# SIM3U166_B register map
File version: 1
CPU: 
Registers are 32-bit, read-write, reset 0x0 unless marked. A register's access mark holds for its fields unless they carry their own. Offsets are from the block's base; [hi:lo] are bit positions; {n}, {i} and the like mark numbered series.

## EPCA_0
Base 0x4000E000
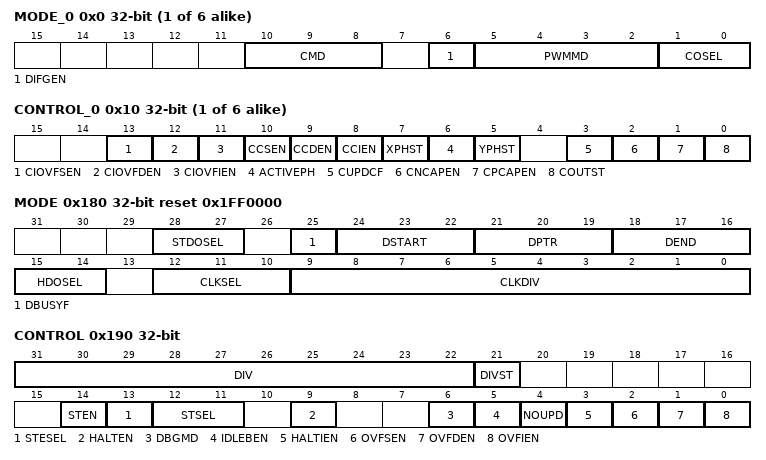
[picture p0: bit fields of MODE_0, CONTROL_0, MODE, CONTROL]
{0x0+0x40*i} MODE_{i} (i=0..5) — Channel Capture/Compare Mode
  [10:8] CMD — Channel Operating Mode.
    0=EDGE_PWM (Configure the channel for edge-aligned PWM mode.); 1=CENTER_ALIGNED_PWM (Configure the channel for center-aligned PWM mode.); 2=HF_SQUARE_WAVE (Configure the channel for high-frequency/square-wave mode.); 3=TIMER_CAPTURE (Configure the channel for timer/capture mode.); 4=N_BIT_PWM (Configure the channel for n-bit edge-aligned PWM mode.)
  [6] DIFGEN — Differential Signal Generator Enable.
    0=DISABLED (Disable the differential signal generator. The channel will output a single non-differential output.); 1=ENABLED (Enable the differential signal generator. The channel will output two differential outputs: X Phase (XPH) and Y Phase (YPH).)
  [5:2] PWMMD — PWM N-Bit Mode.
  [1:0] COSEL — Channel Output Function Select.
    0=TOGGLE_OUTPUT (Toggle the channel output at the next capture/compare, overflow, or intermediate event.); 1=SET_OUTPUT (Set the channel output at the next capture/compare, overflow, or intermediate event.); 2=CLEAR_OUTPUT (Clear the output at the next capture/compare, overflow, or intermediate event.); 3=NO_CHANGE (Capture/Compare, overflow, or intermediate events do not control the output state.)
{0x10+0x40*i} CONTROL_{i} (i=0..5) — Channel Capture/Compare Control
  [13] CIOVFSEN — Intermediate Overflow Synchronization Signal Enable.
    0=DISABLED (Do not send a synchronization signal when a channel intermediate overflow event occurs.); 1=ENABLED (Send a synchronization signal when a channel intermediate overflow occurs.)
  [12] CIOVFDEN — Intermediate Overflow DMA Request Enable.
    0=DISABLED (Do not request DMA data when a channel intermediate overflow event occurs.); 1=ENABLED (Request DMA data when a channel intermediate overflow event occurs.)
  [11] CIOVFIEN — Intermediate Overflow Interrupt Enable.
    0=DISABLED (Disable the channel intermediate overflow interrupt.); 1=ENABLED (Enable the channel intermediate overflow interrupt.)
  [10] CCSEN — Capture/Compare Synchronization Signal Enable.
    0=DISABLED (Do not send a synchronization signal when a channel capture/compare event occurs.); 1=ENABLED (Send a synchronization signal when a channel capture/compare event occurs.)
  [9] CCDEN — Capture/Compare DMA Request Enable.
    0=DISABLED (Do not request DMA data when a channel capture/compare event occurs.); 1=ENABLED (Request DMA data when a channel capture/compare event occurs.)
  [8] CCIEN — Capture/Compare Interrupt Enable.
    0=DISABLED (Disable the channel capture/compare interrupt.); 1=ENABLED (Enable the channel capture/compare interrupt.)
  [7] XPHST — Differential X Phase State.
    0=LOW (Set the X Phase output state to low.); 1=HIGH (Set the X Phase output state to high.)
  [6] ACTIVEPH — Active Channel Select.
    0=YACTIVE (The Y Phase is active and X Phase is inactive.); 1=XACTIVE (The X Phase is active and Y Phase is inactive.)
  [5] YPHST — Differential Y Phase State.
    0=LOW (Set the Y Phase output state to low.); 1=HIGH (Set the Y Phase output state to high.)
  [3] CUPDCF — Channel Register Update Complete Flag.
    0=NOT_SET (A EPCA channel register update completed or is not pending.); 1=SET (A EPCA channel register update has not completed and is still pending.)
  [2] CNCAPEN — Negative Edge Input Capture Enable.
    0=DISABLED (Disable negative-edge input capture.); 1=ENABLED (Enable negative-edge input capture.)
  [1] CPCAPEN — Positive Edge Input Capture Enable.
    0=DISABLED (Disable positive-edge input capture.); 1=ENABLED (Enable positive-edge input capture.)
  [0] COUTST — Channel Output State.
    0=LOW (The channel output state is low.); 1=HIGH (The channel output state is high.)
{0x20+0x40*i} CCAPV_{i} (i=0..5) — Channel Compare Value
  [17:0] CCAPV — Channel Compare Value.
{0x30+0x40*i} CCAPVUPD_{i} (i=0..5) — Channel Compare Update Value
  [17:0] CCAPVUPD — Channel Compare Update Value.
0x180 MODE reset 0x1FF0000 — Module Operating Mode
  [28:27] STDOSEL — Standard Port Bank Output Select.
    0=NO_DIFF (Select the non-differential channel outputs (Channels 0-5) for the standard PB pins.); 1=ONE_DIFF (Select the differential output from Channel 2 and non-differential outputs from Channels 0, 1, 3, and 4 for the standard PB pins.); 2=TWO_DIFF (Select the differential outputs from Channels 1 and 2 and non-differential outputs from Channels 0 and 3 for the standard PB pins.); 3=THREE_DIFF (Select three differential outputs from Channels 0, 1, and 2 for the standard PB pins.)
  [25] DBUSYF — DMA Busy Flag.
    0=IDLE (The DMA channel is not servicing an EPCA control transfer.); 1=BUSY (The DMA channel is busy servicing an EPCA control transfer.)
  [24:22] DSTART — DMA Target Start Index.
    0=LIMIT (Set the first register in a DMA write transfer to LIMITUPD.); {v}=CH{v-1} (Set the first register in a DMA write transfer to Channel {v-1} CCAPVUPD.) (v=1..6); 7=EMPTY (Empty slot.)
  [21:19] DPTR — DMA Write Transfer Pointer.
    0=LIMIT (The DMA channel will write to LIMITUPD next.); {v}=CH{v-1} (The DMA channel will write to Channel {v-1} CCAPVUPD next.) (v=1..6); 7=EMPTY (Empty slot.)
  [18:16] DEND — DMA Write End Index.
    0=LIMIT (Set the last register in a DMA write transfer to LIMITUPD.); {v}=CH{v-1} (Set the last register in a DMA write transfer to Channel {v-1} CCAPVUPD.) (v=1..6); 7=EMPTY (Empty slot.)
  [15:14] HDOSEL — High Drive Port Bank Output Select.
    0=THREE_DIFF (Select three differential outputs from Channels 3, 4, and 5 for the High Drive pins.); 1=TWO_DIFF (Select the differential outputs from Channels 4 and 5 and non-differential outputs from Channels 2 and 3 for the High Drive pins.); 2=ONE_DIFF (Select the differential output from Channel 5 and non-differential outputs from Channels 1-4 for the High Drive pins.); 3=NO_DIFF (Select the non-differential channel outputs (Channels 0-5) for the High Drive pins.)
  [12:10] CLKSEL — Input Clock (F<subscript>CLKIN</subscript>) Select.
    0=APB (Set the APB as the input clock (FCLKIN).); 1=TIMER0 (Set Timer 0 low overflows divided by 2 as the input clock (FCLKIN).); 2=HL_ECI (Set high-to-low transitions on ECI divided by 2 as the input clock (FCLKIN).); 3=EXTOSCN (Set the external oscillator module output (EXTOSCn) divided by 2 as the input clock (FCLKIN).); 4=ECI (Set ECI transitions divided by 2 as the input clock (FCLKIN).)
  [9:0] CLKDIV — Input Clock Divider.
0x190 CONTROL — Module Control
  [31:22] DIV — Current Clock Divider Count.
  [21] DIVST — Clock Divider Output State.
    0=OUTPUT_HIGH (The clock divider is currently in the first half-cycle.); 1=OUTPUT_LOW (The clock divider is currently in the second half-cycle.)
  [14] STEN — Synchronous Input Trigger Enable.
    0=DISABLED (Disable the input trigger (EPCAnTx). The EPCA counter/timer will continue to run if the RUN bit is set regardless of the value on the input trigger.); 1=ENABLED (Enable the input trigger (EPCAnTx). If RUN is set to 1, the EPCA counter/timer will start running when the selected input trigger (STSEL) meets the criteria set by STESEL. It will not stop running if the criteria is no longer met.)
  [13] STESEL — Synchronous Input Trigger Edge Select.
    0=FALLING (A high-to-low transition (falling edge) on EPCAnTx will start the counter/timer.); 1=RISING (A low-to-high transition (rising edge) on EPCAnTx will start the counter/timer.)
  [12:11] STSEL — Synchronous Input Trigger Select.
    0=EPCANT0 (Select input trigger 0, EPCAnT0 (Comparator 0 Output).); 1=EPCANT1 (Select input trigger 1, EPCAnT1 (Comparator 1 Output).); 2=EPCANT2 (Select input trigger 2, EPCAnT2 (Timer 0 High Overflow ).); 3=EPCANT3 (Select input trigger 3, EPCAnT3 (Timer 1 High Overflow).)
  [9] HALTEN — Halt Input Enable.
    0=DISABLED (The Halt input (PB_HDKill) does not affect the EPCA counter/timer.); 1=ENABLED (An assertion of the Halt input (PB_HDKill) will stop the EPCA counter/timer.)
  [6] DBGMD — EPCA Debug Mode.
    0=HALT (A debug breakpoint will stop the EPCA counter/timer.); 1=RUN (The EPCA will continue to operate while the core is halted in debug mode.)
  [5] IDLEBEN — Idle Bypass Enable.
    0=DISABLED (The EPCA module will stop running when the core halts (idle).); 1=ENABLED (The EPCA module will continue normal operation when the core halts (idle).)
  [4] NOUPD — Internal Register Update Inhibit.
    0=INACTIVE (The EPCA registers will automatically load any new update values after an overflow/limit event occurs.); 1=ACTIVE (The EPCA registers will not load any new update values after an overflow/limit event occurs.)
  [3] HALTIEN — EPCA Halt Input Interrupt Enable.
    0=DISABLED (Do not generate an interrupt if the EPCA halt input is high.); 1=ENABLED (Generate an interrupt if the EPCA halt input is high.)
  [2] OVFSEN — EPCA Counter Overflow/Limit Synchronization Signal Enable.
    0=DISABLED (Do not send a synchronization signal when a EPCA counter overflow/limit event occurs.); 1=ENABLED (Send a synchronization signal when a EPCA counter overflow/limit event occurs.)
  [1] OVFDEN — EPCA Counter Overflow/Limit DMA Request Enable.
    0=DISABLED (Do not request DMA data when a EPCA counter overflow/limit event occurs.); 1=ENABLED (Request DMA data when a EPCA counter overflow/limit event occurs.)
  [0] OVFIEN — EPCA Counter Overflow/Limit Interrupt Enable.
    0=DISABLED (Disable the EPCA counter overflow/limit event interrupt.); 1=ENABLED (Enable the EPCA counter overflow/limit event interrupt.)
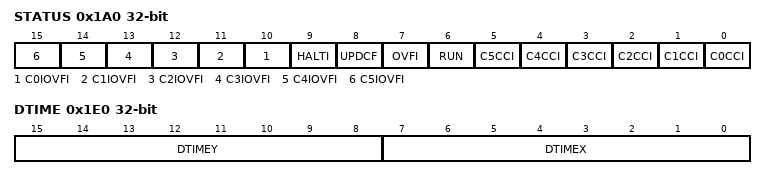
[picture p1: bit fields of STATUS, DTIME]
0x1A0 STATUS — Module Status
  [n+10] C{n}IOVFI (n=0..5) — Channel {n} Intermediate Overflow Interrupt Flag.
    0=NOT_SET (Channel {n} did not count past the channel n-bit mode limit.); 1=SET (Channel {n} counted past the channel n-bit mode limit.)
  [9] HALTI — Halt Input Interrupt Flag.
    0=NOT_SET (The Halt input (PB_HDKill) was not asserted.); 1=SET (The Halt input (PB_HDKill) was asserted.)
  [8] UPDCF — Register Update Complete Flag.
    0=EMPTY (An EPCA register update completed or is not pending.); 1=FULL (An EPCA register update has not completed and is still pending.)
  [7] OVFI — Counter/Timer Overflow/Limit Interrupt Flag.
    0=NOT_SET (An EPCA Counter/Timer overflow/limit event did not occur.); 1=SET (An EPCA Counter/Timer overflow/limit event occurred.)
  [6] RUN — Counter/Timer Run.
    0=STOP (Stop the EPCA Counter/Timer.); 1=START (Start the EPCA Counter/Timer.)
  [n] C{n}CCI (n=0..5) — Channel {n} Capture/Compare Interrupt Flag.
    0=NOT_SET (A Channel {n} match or capture event did not occur.); 1=SET (A Channel {n} match or capture event occurred.)
0x1B0 COUNTER — Module Counter/Timer
  [15:0] COUNTER — Counter/Timer.
0x1C0 LIMIT reset 0xFFFF — Module Upper Limit
  [15:0] LIMIT — Upper Limit.
0x1D0 LIMITUPD — Module Upper Limit Update Value
  [15:0] LIMITUPD — Module Upper Limit Update Value.
0x1E0 DTIME — Phase Delay Time
  [15:8] DTIMEY — Y Phase Delay Time.
  [7:0] DTIMEX — X Phase Delay Time.
0x200 DTARGET — DMA Transfer Target
  [31:0] DTARGET wo — DMA Transfer Target.
